# nrf9220_cellrf register map
Vendor: Nordic Semiconductor; Series: nRF92; File version: 1
CPU: CM0 r0p0, little endian, no MPU, no FPU, 2 interrupt priority bits, 33 interrupts
Registers are 32-bit, read-write, reset 0x0 unless marked. A register's access mark holds for its fields unless they carry their own. Offsets are from the block's base; [hi:lo] are bit positions.

## SX (part 2 of 3) — Ahma SX register map SX register map
Base 0x46147000
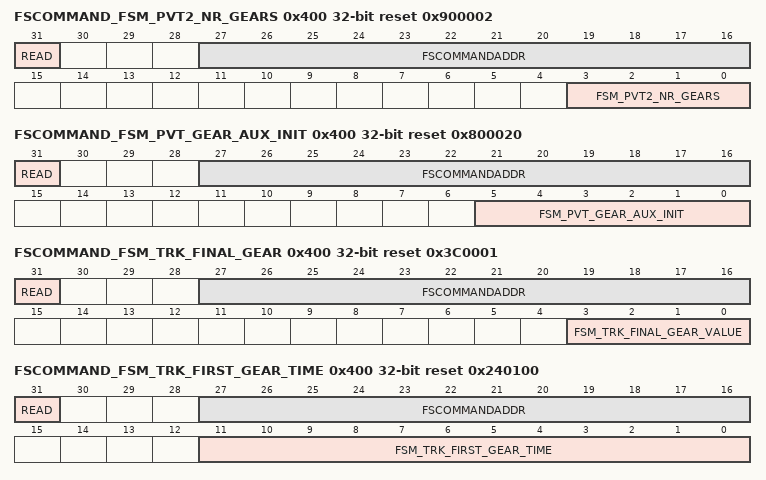
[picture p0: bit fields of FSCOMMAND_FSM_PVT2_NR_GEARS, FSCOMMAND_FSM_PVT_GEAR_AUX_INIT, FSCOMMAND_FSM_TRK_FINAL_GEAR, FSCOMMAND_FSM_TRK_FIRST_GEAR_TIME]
0x400 FSCOMMAND_FSM_PVT2_NR_GEARS reset 0x900002 (alternate view of FSCOMMAND_ANA_ISOLATION) — Send or receive command directly to/from the AdPllLte digital island. Only write to this register when FSASYNCBUSBUSY returns 0
  [31] READ — When 1, a read transaction is initiated. When the event COMPLETETRANS is set, read back this register
  [27:16] FSCOMMANDADDR — Address for the async interface. ALWAYS 0x90.
    144=FSM_PVT2_NR_GEARS_ADDR (ALWAYS 0x90.)
  [3:0] FSM_PVT2_NR_GEARS — The start value for the gear in NormPvt in PVT2 state. Used both in AdPllFsm and AdPllNormPvt. It affects how long we will be in the PVT2 state
0x400 FSCOMMAND_FSM_PVT_GEAR_AUX_INIT reset 0x800020 (alternate view of FSCOMMAND_ANA_ISOLATION) — Send or receive command directly to/from the AdPllLte digital island. Only write to this register when FSASYNCBUSBUSY returns 0
  [31] READ — When 1, a read transaction is initiated. When the event COMPLETETRANS is set, read back this register
  [27:16] FSCOMMANDADDR — Address for the async interface. ALWAYS 0x80.
    128=FSM_PVT_GEAR_AUX_INIT_ADDR (ALWAYS 0x80.)
  [5:0] FSM_PVT_GEAR_AUX_INIT — The start value for the gear_aux value in NormPvt. gear_aux is decremented at regular intervals, and is the upper bound for the current gear setting in NormPvt
0x400 FSCOMMAND_FSM_TRK_FINAL_GEAR reset 0x3C0001 (alternate view of FSCOMMAND_ANA_ISOLATION) — Send or receive command directly to/from the AdPllLte digital island. Only write to this register when FSASYNCBUSBUSY returns 0
  [31] READ — When 1, a read transaction is initiated. When the event COMPLETETRANS is set, read back this register
  [27:16] FSCOMMANDADDR — Address for the async interface. ALWAYS 0x3C.
    60=FSM_TRK_FINAL_GEAR_ADDR (ALWAYS 0x3C.)
  [3:0] FSM_TRK_FINAL_GEAR_VALUE — The gear setting used for the TRK bank after lock. Mainly a debug setting.
0x400 FSCOMMAND_FSM_TRK_FIRST_GEAR_TIME reset 0x240100 (alternate view of FSCOMMAND_ANA_ISOLATION) — Send or receive command directly to/from the AdPllLte digital island. Only write to this register when FSASYNCBUSBUSY returns 0
  [31] READ — When 1, a read transaction is initiated. When the event COMPLETETRANS is set, read back this register
  [27:16] FSCOMMANDADDR — Address for the async interface. ALWAYS 0x24.
    36=FSM_TRK_FIRST_GEAR_TIME_ADDR (ALWAYS 0x24.)
  [11:0] FSM_TRK_FIRST_GEAR_TIME — The number of cycles before we change gear in TRK state the first time. Used in AdPllFsm
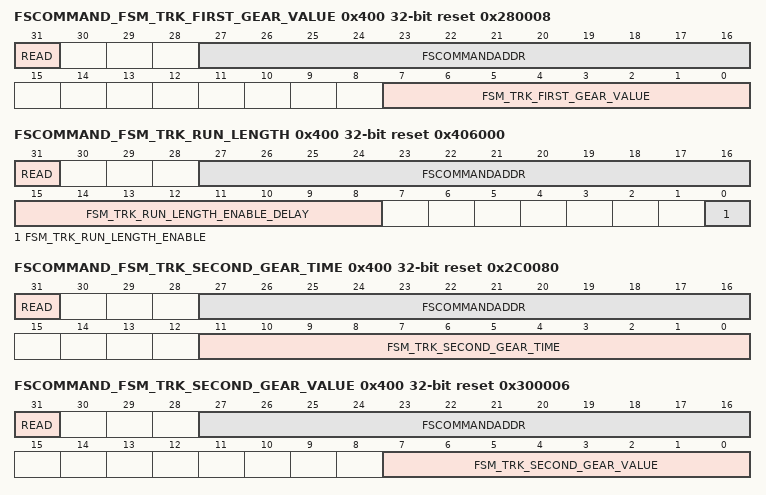
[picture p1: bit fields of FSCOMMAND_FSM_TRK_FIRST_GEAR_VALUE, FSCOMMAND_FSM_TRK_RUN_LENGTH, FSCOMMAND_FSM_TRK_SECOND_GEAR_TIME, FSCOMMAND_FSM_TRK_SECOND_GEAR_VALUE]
0x400 FSCOMMAND_FSM_TRK_FIRST_GEAR_VALUE reset 0x280008 (alternate view of FSCOMMAND_ANA_ISOLATION) — Send or receive command directly to/from the AdPllLte digital island. Only write to this register when FSASYNCBUSBUSY returns 0
  [31] READ — When 1, a read transaction is initiated. When the event COMPLETETRANS is set, read back this register
  [27:16] FSCOMMANDADDR — Address for the async interface. ALWAYS 0x28.
    40=FSM_TRK_FIRST_GEAR_VALUE_ADDR (ALWAYS 0x28.)
  [7:0] FSM_TRK_FIRST_GEAR_VALUE — The first gear value in TRK state
0x400 FSCOMMAND_FSM_TRK_RUN_LENGTH reset 0x406000 (alternate view of FSCOMMAND_ANA_ISOLATION) — Send or receive command directly to/from the AdPllLte digital island. Only write to this register when FSASYNCBUSBUSY returns 0
  [31] READ — When 1, a read transaction is initiated. When the event COMPLETETRANS is set, read back this register
  [27:16] FSCOMMANDADDR — Address for the async interface. ALWAYS 0x40.
    64=FSM_TRK_RUN_LENGTH_ADDR (ALWAYS 0x40.)
  [15:8] FSM_TRK_RUN_LENGTH_ENABLE_DELAY — Delay for enabling runlength delay
  [0] FSM_TRK_RUN_LENGTH_ENABLE — Selects whether to enable a feature where the gear in TRK state is slowed down if 'phe' stays the same for a while
0x400 FSCOMMAND_FSM_TRK_SECOND_GEAR_TIME reset 0x2C0080 (alternate view of FSCOMMAND_ANA_ISOLATION) — Send or receive command directly to/from the AdPllLte digital island. Only write to this register when FSASYNCBUSBUSY returns 0
  [31] READ — When 1, a read transaction is initiated. When the event COMPLETETRANS is set, read back this register
  [27:16] FSCOMMANDADDR — Address for the async interface. ALWAYS 0x2C.
    44=FSM_TRK_SECOND_GEAR_TIME_ADDR (ALWAYS 0x2C.)
  [11:0] FSM_TRK_SECOND_GEAR_TIME — The number of cycles before we change gear in TRK state the second time. Used in AdPllFsm
0x400 FSCOMMAND_FSM_TRK_SECOND_GEAR_VALUE reset 0x300006 (alternate view of FSCOMMAND_ANA_ISOLATION) — Send or receive command directly to/from the AdPllLte digital island. Only write to this register when FSASYNCBUSBUSY returns 0
  [31] READ — When 1, a read transaction is initiated. When the event COMPLETETRANS is set, read back this register
  [27:16] FSCOMMANDADDR — Address for the async interface. ALWAYS 0x30.
    48=FSM_TRK_SECOND_GEAR_VALUE_ADDR (ALWAYS 0x30.)
  [7:0] FSM_TRK_SECOND_GEAR_VALUE — The second gear value in TRK state
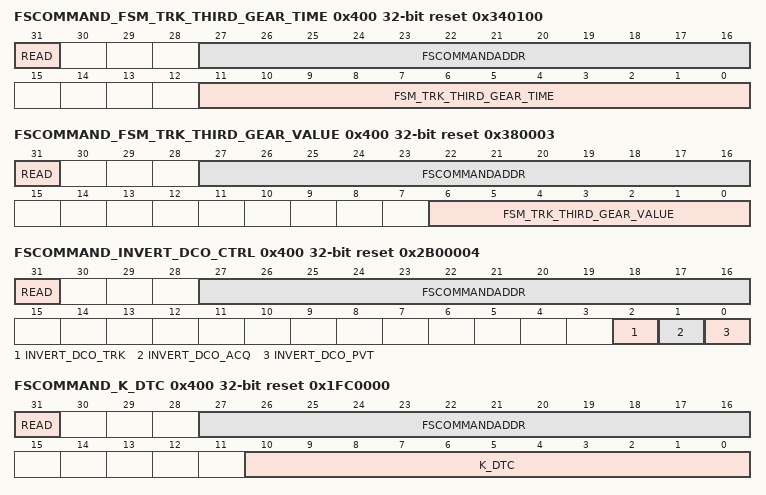
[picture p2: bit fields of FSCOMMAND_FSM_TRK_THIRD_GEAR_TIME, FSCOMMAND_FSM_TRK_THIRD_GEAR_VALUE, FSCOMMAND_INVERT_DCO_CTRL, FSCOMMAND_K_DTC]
0x400 FSCOMMAND_FSM_TRK_THIRD_GEAR_TIME reset 0x340100 (alternate view of FSCOMMAND_ANA_ISOLATION) — Send or receive command directly to/from the AdPllLte digital island. Only write to this register when FSASYNCBUSBUSY returns 0
  [31] READ — When 1, a read transaction is initiated. When the event COMPLETETRANS is set, read back this register
  [27:16] FSCOMMANDADDR — Address for the async interface. ALWAYS 0x34.
    52=FSM_TRK_THIRD_GEAR_TIME_ADDR (ALWAYS 0x34.)
  [11:0] FSM_TRK_THIRD_GEAR_TIME — The number of cycles before we change gear in TRK statethe third time. Used in AdPllFsm
0x400 FSCOMMAND_FSM_TRK_THIRD_GEAR_VALUE reset 0x380003 (alternate view of FSCOMMAND_ANA_ISOLATION) — Send or receive command directly to/from the AdPllLte digital island. Only write to this register when FSASYNCBUSBUSY returns 0
  [31] READ — When 1, a read transaction is initiated. When the event COMPLETETRANS is set, read back this register
  [27:16] FSCOMMANDADDR — Address for the async interface. ALWAYS 0x38.
    56=FSM_TRK_THIRD_GEAR_VALUE_ADDR (ALWAYS 0x38.)
  [6:0] FSM_TRK_THIRD_GEAR_VALUE — The third gear value in TRK state
0x400 FSCOMMAND_INVERT_DCO_CTRL reset 0x2B00004 (alternate view of FSCOMMAND_ANA_ISOLATION) — Send or receive command directly to/from the AdPllLte digital island. Only write to this register when FSASYNCBUSBUSY returns 0
  [31] READ — When 1, a read transaction is initiated. When the event COMPLETETRANS is set, read back this register
  [27:16] FSCOMMANDADDR — Address for the async interface. ALWAYS 0x2B0.
    0x2B0=INVERT_DCO_CTRL_ADDR (ALWAYS 0x2B0.)
  [2] INVERT_DCO_TRK — Invert DCO TRK control word
  [1] INVERT_DCO_ACQ — Invert DCO ACQ control word
  [0] INVERT_DCO_PVT — Invert DCO PVT control word
0x400 FSCOMMAND_K_DTC reset 0x1FC0000 (alternate view of FSCOMMAND_ANA_ISOLATION) — Send or receive command directly to/from the AdPllLte digital island. Only write to this register when FSASYNCBUSBUSY returns 0
  [31] READ — When 1, a read transaction is initiated. When the event COMPLETETRANS is set, read back this register
  [27:16] FSCOMMANDADDR — Address for the async interface. ALWAYS 0x1FC.
    0x1FC=K_DTC_ADDR (ALWAYS 0x1FC.)
  [10:0] K_DTC — Read the current kDTC estimate
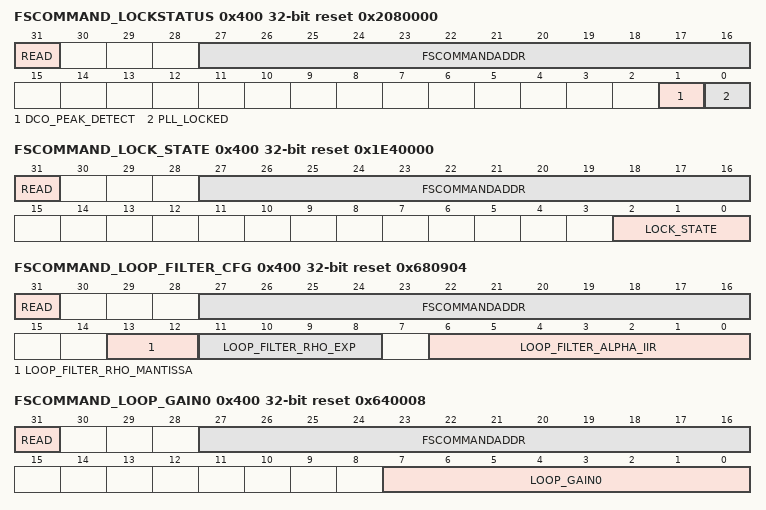
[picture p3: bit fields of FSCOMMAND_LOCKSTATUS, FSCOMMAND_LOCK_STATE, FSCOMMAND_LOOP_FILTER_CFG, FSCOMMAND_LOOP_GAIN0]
0x400 FSCOMMAND_LOCKSTATUS reset 0x2080000 (alternate view of FSCOMMAND_ANA_ISOLATION) — Send or receive command directly to/from the AdPllLte digital island. Only write to this register when FSASYNCBUSBUSY returns 0
  [31] READ — When 1, a read transaction is initiated. When the event COMPLETETRANS is set, read back this register
  [27:16] FSCOMMANDADDR — Address for the async interface. ALWAYS 0x208.
    0x208=LOCKSTATUS_ADDR (ALWAYS 0x208.)
  [1] DCO_PEAK_DETECT — Read the peakDetect signal from the analog domain
  [0] PLL_LOCKED — Read the pllLocked signal
0x400 FSCOMMAND_LOCK_STATE reset 0x1E40000 (alternate view of FSCOMMAND_ANA_ISOLATION) — Send or receive command directly to/from the AdPllLte digital island. Only write to this register when FSASYNCBUSBUSY returns 0
  [31] READ — When 1, a read transaction is initiated. When the event COMPLETETRANS is set, read back this register
  [27:16] FSCOMMANDADDR — Address for the async interface. ALWAYS 0x1E4.
    0x1E4=LOCK_STATE_ADDR (ALWAYS 0x1E4.)
  [2:0] LOCK_STATE — Read the current state in the locking state machine
0x400 FSCOMMAND_LOOP_FILTER_CFG reset 0x680904 (alternate view of FSCOMMAND_ANA_ISOLATION) — Send or receive command directly to/from the AdPllLte digital island. Only write to this register when FSASYNCBUSBUSY returns 0
  [31] READ — When 1, a read transaction is initiated. When the event COMPLETETRANS is set, read back this register
  [27:16] FSCOMMANDADDR — Address for the async interface. ALWAYS 0x68.
    104=LOOP_FILTER_CFG_ADDR (ALWAYS 0x68.)
  [13:12] LOOP_FILTER_RHO_MANTISSA — The rho value used in the loop filter in TRK bank control
  [11:8] LOOP_FILTER_RHO_EXP — The rho value used in the loop filter in TRK bank control
  [6:0] LOOP_FILTER_ALPHA_IIR — The alpha value used in the TRK bank control IIR filter (only when gear is 1. Otherwise, the alpha value is set to 64)
0x400 FSCOMMAND_LOOP_GAIN0 reset 0x640008 (alternate view of FSCOMMAND_ANA_ISOLATION) — Send or receive command directly to/from the AdPllLte digital island. Only write to this register when FSASYNCBUSBUSY returns 0
  [31] READ — When 1, a read transaction is initiated. When the event COMPLETETRANS is set, read back this register
  [27:16] FSCOMMANDADDR — Address for the async interface. ALWAYS 0x64.
    100=LOOP_GAIN0_ADDR (ALWAYS 0x64.)
  [7:0] LOOP_GAIN0 — How much the TDC output value is scaled and thus how much the error it will affect the loop. Default value.
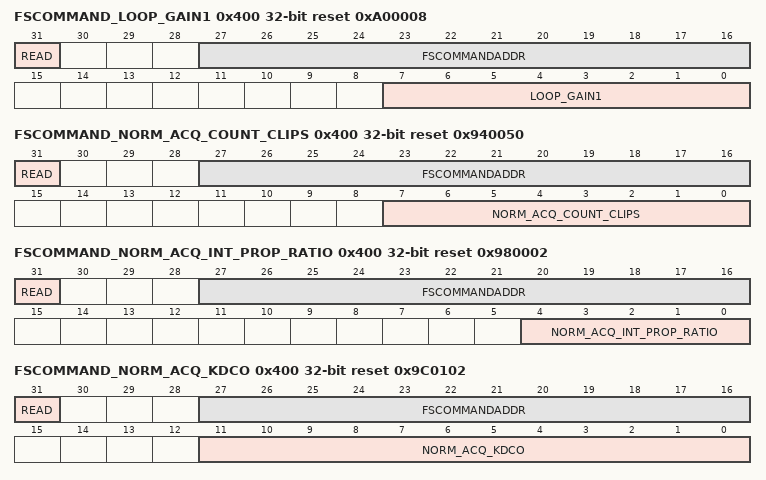
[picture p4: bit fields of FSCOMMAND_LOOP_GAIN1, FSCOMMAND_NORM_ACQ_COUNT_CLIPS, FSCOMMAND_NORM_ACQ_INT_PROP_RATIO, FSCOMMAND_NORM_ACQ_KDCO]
0x400 FSCOMMAND_LOOP_GAIN1 reset 0xA00008 (alternate view of FSCOMMAND_ANA_ISOLATION) — Send or receive command directly to/from the AdPllLte digital island. Only write to this register when FSASYNCBUSBUSY returns 0
  [31] READ — When 1, a read transaction is initiated. When the event COMPLETETRANS is set, read back this register
  [27:16] FSCOMMANDADDR — Address for the async interface. ALWAYS 0xA0.
    160=LOOP_GAIN1_ADDR (ALWAYS 0xA0.)
  [7:0] LOOP_GAIN1 — How much the TDC output value is scaled and thus how much the error it will affect the loop. Alternative value for fast frequency jump.
0x400 FSCOMMAND_NORM_ACQ_COUNT_CLIPS reset 0x940050 (alternate view of FSCOMMAND_ANA_ISOLATION) — Send or receive command directly to/from the AdPllLte digital island. Only write to this register when FSASYNCBUSBUSY returns 0
  [31] READ — When 1, a read transaction is initiated. When the event COMPLETETRANS is set, read back this register
  [27:16] FSCOMMANDADDR — Address for the async interface. ALWAYS 0x94.
    148=NORM_ACQ_COUNT_CLIPS_ADDR (ALWAYS 0x94.)
  [7:0] NORM_ACQ_COUNT_CLIPS — The ACQ bank overflow happens if the value stays outside min/max of ACQ for more than this number of cycles. In the case of overflow the PVT capacitor bank control value is incremented
0x400 FSCOMMAND_NORM_ACQ_INT_PROP_RATIO reset 0x980002 (alternate view of FSCOMMAND_ANA_ISOLATION) — Send or receive command directly to/from the AdPllLte digital island. Only write to this register when FSASYNCBUSBUSY returns 0
  [31] READ — When 1, a read transaction is initiated. When the event COMPLETETRANS is set, read back this register
  [27:16] FSCOMMANDADDR — Address for the async interface. ALWAYS 0x98.
    152=NORM_ACQ_INT_PROP_RATIO_ADDR (ALWAYS 0x98.)
  [4:0] NORM_ACQ_INT_PROP_RATIO — The integral path in the ACQ capacitor control will be right-shifted (divided by 2 N times) this number. It basically selects how big impact the integral path has vs the proportional path. (Bigger number - less impact)
0x400 FSCOMMAND_NORM_ACQ_KDCO reset 0x9C0102 (alternate view of FSCOMMAND_ANA_ISOLATION) — Send or receive command directly to/from the AdPllLte digital island. Only write to this register when FSASYNCBUSBUSY returns 0
  [31] READ — When 1, a read transaction is initiated. When the event COMPLETETRANS is set, read back this register
  [27:16] FSCOMMANDADDR — Address for the async interface. ALWAYS 0x9C.
    156=NORM_ACQ_KDCO_ADDR (ALWAYS 0x9C.)
  [11:0] NORM_ACQ_KDCO — The estimated kDCO for steps of the control word in the ACQ capacitor bank. Used in AdPllNormPvt to scale the error input.
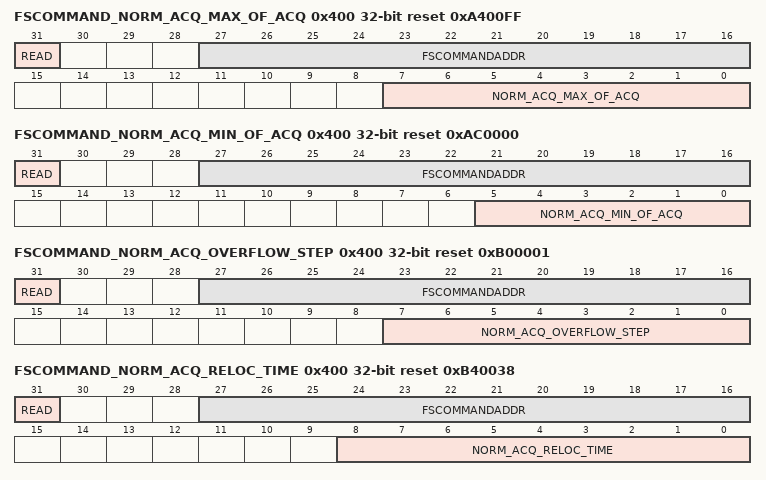
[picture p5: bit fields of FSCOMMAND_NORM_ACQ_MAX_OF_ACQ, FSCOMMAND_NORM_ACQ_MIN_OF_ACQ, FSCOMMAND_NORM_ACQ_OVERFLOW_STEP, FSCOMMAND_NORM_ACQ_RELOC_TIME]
0x400 FSCOMMAND_NORM_ACQ_MAX_OF_ACQ reset 0xA400FF (alternate view of FSCOMMAND_ANA_ISOLATION) — Send or receive command directly to/from the AdPllLte digital island. Only write to this register when FSASYNCBUSBUSY returns 0
  [31] READ — When 1, a read transaction is initiated. When the event COMPLETETRANS is set, read back this register
  [27:16] FSCOMMANDADDR — Address for the async interface. ALWAYS 0xA4.
    164=NORM_ACQ_MAX_OF_ACQ_ADDR (ALWAYS 0xA4.)
  [7:0] NORM_ACQ_MAX_OF_ACQ — The allowed maximum value for the control word for the ACQ capacitor bank before the control word for the PVT capacitor bank will be incremented
0x400 FSCOMMAND_NORM_ACQ_MIN_OF_ACQ reset 0xAC0000 (alternate view of FSCOMMAND_ANA_ISOLATION) — Send or receive command directly to/from the AdPllLte digital island. Only write to this register when FSASYNCBUSBUSY returns 0
  [31] READ — When 1, a read transaction is initiated. When the event COMPLETETRANS is set, read back this register
  [27:16] FSCOMMANDADDR — Address for the async interface. ALWAYS 0xAC.
    172=NORM_ACQ_MIN_OF_ACQ_ADDR (ALWAYS 0xAC.)
  [5:0] NORM_ACQ_MIN_OF_ACQ — The allowed maximum value for the control word for the ACQ capacitor bank before the control word for the PVT capacitor bank will be incremented
0x400 FSCOMMAND_NORM_ACQ_OVERFLOW_STEP reset 0xB00001 (alternate view of FSCOMMAND_ANA_ISOLATION) — Send or receive command directly to/from the AdPllLte digital island. Only write to this register when FSASYNCBUSBUSY returns 0
  [31] READ — When 1, a read transaction is initiated. When the event COMPLETETRANS is set, read back this register
  [27:16] FSCOMMANDADDR — Address for the async interface. ALWAYS 0xB0.
    176=NORM_ACQ_OVERFLOW_STEP_ADDR (ALWAYS 0xB0.)
  [7:0] NORM_ACQ_OVERFLOW_STEP — The number of steps to adjust the ACQ capacitor bank when an overflow is detected in the TRK capacitor bank
0x400 FSCOMMAND_NORM_ACQ_RELOC_TIME reset 0xB40038 (alternate view of FSCOMMAND_ANA_ISOLATION) — Send or receive command directly to/from the AdPllLte digital island. Only write to this register when FSASYNCBUSBUSY returns 0
  [31] READ — When 1, a read transaction is initiated. When the event COMPLETETRANS is set, read back this register
  [27:16] FSCOMMANDADDR — Address for the async interface. ALWAYS 0xB4.
    180=NORM_ACQ_RELOC_TIME_ADDR (ALWAYS 0xB4.)
  [8:0] NORM_ACQ_RELOC_TIME — Minimum time between ACQ overflows
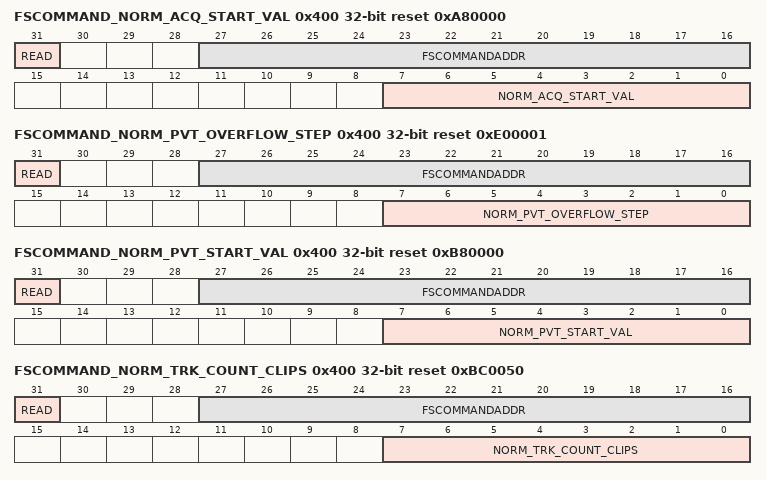
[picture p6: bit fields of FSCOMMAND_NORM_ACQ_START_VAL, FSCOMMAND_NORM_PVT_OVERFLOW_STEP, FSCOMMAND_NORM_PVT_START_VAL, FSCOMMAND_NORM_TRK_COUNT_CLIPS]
0x400 FSCOMMAND_NORM_ACQ_START_VAL reset 0xA80000 (alternate view of FSCOMMAND_ANA_ISOLATION) — Send or receive command directly to/from the AdPllLte digital island. Only write to this register when FSASYNCBUSBUSY returns 0
  [31] READ — When 1, a read transaction is initiated. When the event COMPLETETRANS is set, read back this register
  [27:16] FSCOMMANDADDR — Address for the async interface. ALWAYS 0xA8.
    168=NORM_ACQ_START_VAL_ADDR (ALWAYS 0xA8.)
  [7:0] NORM_ACQ_START_VAL — The start value for the control word for the ACQ capactior bank (signed offset from mid code)
0x400 FSCOMMAND_NORM_PVT_OVERFLOW_STEP reset 0xE00001 (alternate view of FSCOMMAND_ANA_ISOLATION) — Send or receive command directly to/from the AdPllLte digital island. Only write to this register when FSASYNCBUSBUSY returns 0
  [31] READ — When 1, a read transaction is initiated. When the event COMPLETETRANS is set, read back this register
  [27:16] FSCOMMANDADDR — Address for the async interface. ALWAYS 0xE0.
    224=NORM_PVT_OVERFLOW_STEP_ADDR (ALWAYS 0xE0.)
  [7:0] NORM_PVT_OVERFLOW_STEP — Number of correction steps to make in NormPvt when there is an overflow being indicated by NormAcq
0x400 FSCOMMAND_NORM_PVT_START_VAL reset 0xB80000 (alternate view of FSCOMMAND_ANA_ISOLATION) — Send or receive command directly to/from the AdPllLte digital island. Only write to this register when FSASYNCBUSBUSY returns 0
  [31] READ — When 1, a read transaction is initiated. When the event COMPLETETRANS is set, read back this register
  [27:16] FSCOMMANDADDR — Address for the async interface. ALWAYS 0xB8.
    184=NORM_PVT_START_VAL_ADDR (ALWAYS 0xB8.)
  [7:0] NORM_PVT_START_VAL — The start value for the control word for the PVT capacitor bank (signed offset from mid code)
0x400 FSCOMMAND_NORM_TRK_COUNT_CLIPS reset 0xBC0050 (alternate view of FSCOMMAND_ANA_ISOLATION) — Send or receive command directly to/from the AdPllLte digital island. Only write to this register when FSASYNCBUSBUSY returns 0
  [31] READ — When 1, a read transaction is initiated. When the event COMPLETETRANS is set, read back this register
  [27:16] FSCOMMANDADDR — Address for the async interface. ALWAYS 0xBC.
    188=NORM_TRK_COUNT_CLIPS_ADDR (ALWAYS 0xBC.)
  [7:0] NORM_TRK_COUNT_CLIPS — The TRK bank overflow happens if the value stays outside min/max of TRK for more than this number of cycles. If it does, we signal an TRK bank overflow and bump the ACQ control word, and lower the TRK control word.
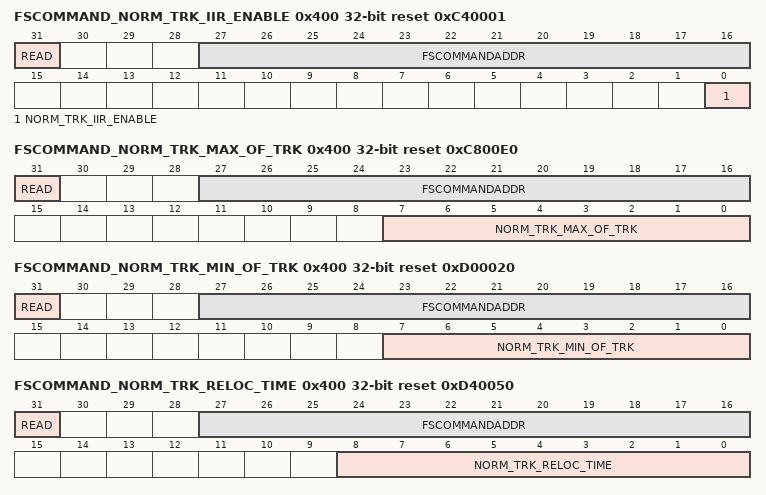
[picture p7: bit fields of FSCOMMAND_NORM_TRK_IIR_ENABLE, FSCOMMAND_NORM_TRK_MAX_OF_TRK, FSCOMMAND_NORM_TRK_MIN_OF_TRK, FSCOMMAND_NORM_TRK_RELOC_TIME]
0x400 FSCOMMAND_NORM_TRK_IIR_ENABLE reset 0xC40001 (alternate view of FSCOMMAND_ANA_ISOLATION) — Send or receive command directly to/from the AdPllLte digital island. Only write to this register when FSASYNCBUSBUSY returns 0
  [31] READ — When 1, a read transaction is initiated. When the event COMPLETETRANS is set, read back this register
  [27:16] FSCOMMANDADDR — Address for the async interface. ALWAYS 0xC4.
    196=NORM_TRK_IIR_ENABLE_ADDR (ALWAYS 0xC4.)
  [0] NORM_TRK_IIR_ENABLE — Enable the IIR filter in the TRK bank control
0x400 FSCOMMAND_NORM_TRK_MAX_OF_TRK reset 0xC800E0 (alternate view of FSCOMMAND_ANA_ISOLATION) — Send or receive command directly to/from the AdPllLte digital island. Only write to this register when FSASYNCBUSBUSY returns 0
  [31] READ — When 1, a read transaction is initiated. When the event COMPLETETRANS is set, read back this register
  [27:16] FSCOMMANDADDR — Address for the async interface. ALWAYS 0xC8.
    200=NORM_TRK_MAX_OF_TRK_ADDR (ALWAYS 0xC8.)
  [7:0] NORM_TRK_MAX_OF_TRK — Max allowed value in the TRK control before the safety mechanism starts counting
0x400 FSCOMMAND_NORM_TRK_MIN_OF_TRK reset 0xD00020 (alternate view of FSCOMMAND_ANA_ISOLATION) — Send or receive command directly to/from the AdPllLte digital island. Only write to this register when FSASYNCBUSBUSY returns 0
  [31] READ — When 1, a read transaction is initiated. When the event COMPLETETRANS is set, read back this register
  [27:16] FSCOMMANDADDR — Address for the async interface. ALWAYS 0xD0.
    208=NORM_TRK_MIN_OF_TRK_ADDR (ALWAYS 0xD0.)
  [7:0] NORM_TRK_MIN_OF_TRK — Min allowed value in the TRK control before the safety mechanism starts counting
0x400 FSCOMMAND_NORM_TRK_RELOC_TIME reset 0xD40050 (alternate view of FSCOMMAND_ANA_ISOLATION) — Send or receive command directly to/from the AdPllLte digital island. Only write to this register when FSASYNCBUSBUSY returns 0
  [31] READ — When 1, a read transaction is initiated. When the event COMPLETETRANS is set, read back this register
  [27:16] FSCOMMANDADDR — Address for the async interface. ALWAYS 0xD4.
    212=NORM_TRK_RELOC_TIME_ADDR (ALWAYS 0xD4.)
  [8:0] NORM_TRK_RELOC_TIME — Minimum time before and between TRK overflows
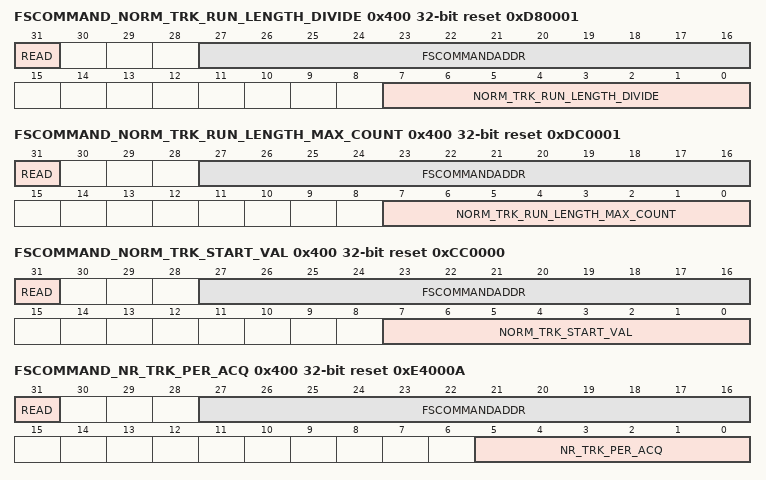
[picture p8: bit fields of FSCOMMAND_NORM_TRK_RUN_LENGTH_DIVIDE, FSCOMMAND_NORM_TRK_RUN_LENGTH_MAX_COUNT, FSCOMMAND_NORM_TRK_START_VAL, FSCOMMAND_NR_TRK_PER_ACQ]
0x400 FSCOMMAND_NORM_TRK_RUN_LENGTH_DIVIDE reset 0xD80001 (alternate view of FSCOMMAND_ANA_ISOLATION) — Send or receive command directly to/from the AdPllLte digital island. Only write to this register when FSASYNCBUSBUSY returns 0
  [31] READ — When 1, a read transaction is initiated. When the event COMPLETETRANS is set, read back this register
  [27:16] FSCOMMANDADDR — Address for the async interface. ALWAYS 0xD8.
    216=NORM_TRK_RUN_LENGTH_DIVIDE_ADDR (ALWAYS 0xD8.)
  [7:0] NORM_TRK_RUN_LENGTH_DIVIDE — When using run length division. This number decides how much to divide
0x400 FSCOMMAND_NORM_TRK_RUN_LENGTH_MAX_COUNT reset 0xDC0001 (alternate view of FSCOMMAND_ANA_ISOLATION) — Send or receive command directly to/from the AdPllLte digital island. Only write to this register when FSASYNCBUSBUSY returns 0
  [31] READ — When 1, a read transaction is initiated. When the event COMPLETETRANS is set, read back this register
  [27:16] FSCOMMANDADDR — Address for the async interface. ALWAYS 0xDC.
    220=NORM_TRK_RUN_LENGTH_MAX_COUNT_ADDR (ALWAYS 0xDC.)
  [7:0] NORM_TRK_RUN_LENGTH_MAX_COUNT — The max value to count to when using run length division
0x400 FSCOMMAND_NORM_TRK_START_VAL reset 0xCC0000 (alternate view of FSCOMMAND_ANA_ISOLATION) — Send or receive command directly to/from the AdPllLte digital island. Only write to this register when FSASYNCBUSBUSY returns 0
  [31] READ — When 1, a read transaction is initiated. When the event COMPLETETRANS is set, read back this register
  [27:16] FSCOMMANDADDR — Address for the async interface. ALWAYS 0xCC.
    204=NORM_TRK_START_VAL_ADDR (ALWAYS 0xCC.)
  [7:0] NORM_TRK_START_VAL — Start value for the TRK bank control (signed offset from mid code)
0x400 FSCOMMAND_NR_TRK_PER_ACQ reset 0xE4000A (alternate view of FSCOMMAND_ANA_ISOLATION) — Send or receive command directly to/from the AdPllLte digital island. Only write to this register when FSASYNCBUSBUSY returns 0
  [31] READ — When 1, a read transaction is initiated. When the event COMPLETETRANS is set, read back this register
  [27:16] FSCOMMANDADDR — Address for the async interface. ALWAYS 0xE4.
    228=NR_TRK_PER_ACQ_ADDR (ALWAYS 0xE4.)
  [5:0] NR_TRK_PER_ACQ — The ACQ capacitance divided by TRK capacitance. This is used to know how much to subtract from the TRK control value when the ACQ control value is bumped.
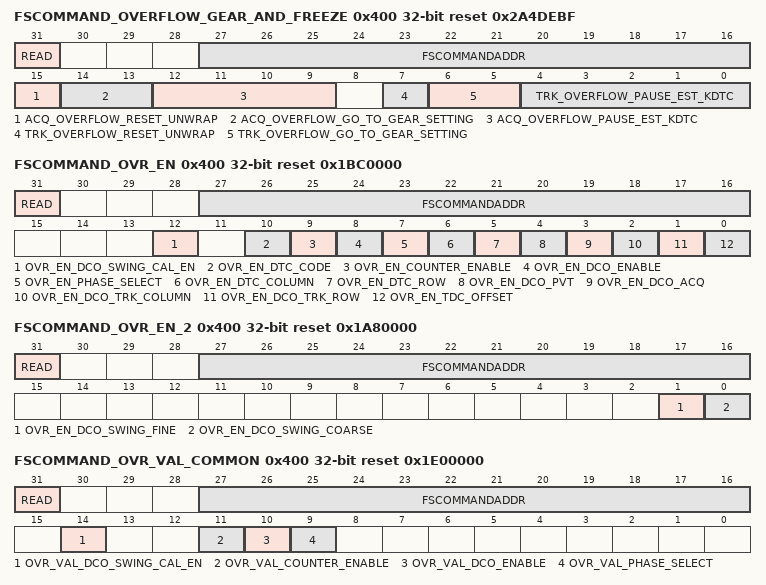
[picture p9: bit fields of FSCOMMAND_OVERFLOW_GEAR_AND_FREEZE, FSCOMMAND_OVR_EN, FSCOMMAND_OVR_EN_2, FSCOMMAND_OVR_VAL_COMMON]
0x400 FSCOMMAND_OVERFLOW_GEAR_AND_FREEZE reset 0x2A4DEBF (alternate view of FSCOMMAND_ANA_ISOLATION) — Send or receive command directly to/from the AdPllLte digital island. Only write to this register when FSASYNCBUSBUSY returns 0
  [31] READ — When 1, a read transaction is initiated. When the event COMPLETETRANS is set, read back this register
  [27:16] FSCOMMANDADDR — Address for the async interface. ALWAYS 0x2A4.
    0x2A4=OVERFLOW_GEAR_AND_FREEZE_ADDR (ALWAYS 0x2A4.)
  [15] ACQ_OVERFLOW_RESET_UNWRAP — Reset the unwrap accumulator when overflowing the ACQ bank and stepping the PVT bank
  [14:13] ACQ_OVERFLOW_GO_TO_GEAR_SETTING — Go to one of the configured gear settings when the ACQ bank overflows. 0: off, 1: Go to FSM_TRK_THIRD_GEAR, 2: Go to FSM_TRK_SECOND_GEAR, 3: Go to FSM_TRK_FIRST_GEAR
  [12:9] ACQ_OVERFLOW_PAUSE_EST_KDTC — When the ACQ bank overflows, we disable the input to the kDTC estimator for a while (multiplied by 16)
  [7] TRK_OVERFLOW_RESET_UNWRAP — Reset the unwrap accumulator when overflowing the TRK bank and stepping the ACQ bank
  [6:5] TRK_OVERFLOW_GO_TO_GEAR_SETTING — Go to one of the configured gear settings when the TRK bank overflows. 0: off, 1: Go to FSM_TRK_THIRD_GEAR, 2: Go to FSM_TRK_SECOND_GEAR, 3: Go to FSM_TRK_FIRST_GEAR
  [4:0] TRK_OVERFLOW_PAUSE_EST_KDTC — When the TRK bank overflows, we disable the input to the kDTC estimator for a while (multiplied by 8)
0x400 FSCOMMAND_OVR_EN reset 0x1BC0000 (alternate view of FSCOMMAND_ANA_ISOLATION) — Send or receive command directly to/from the AdPllLte digital island. Only write to this register when FSASYNCBUSBUSY returns 0
  [31] READ — When 1, a read transaction is initiated. When the event COMPLETETRANS is set, read back this register
  [27:16] FSCOMMANDADDR — Address for the async interface. ALWAYS 0x1BC.
    0x1BC=OVR_EN_ADDR (ALWAYS 0x1BC.)
  [12] OVR_EN_DCO_SWING_CAL_EN — Override enable for dcoSwingCalEn
  [10] OVR_EN_DTC_CODE — Override enable for the DTC control code
  [9] OVR_EN_COUNTER_ENABLE — Override enable for fsCounterEnable
  [8] OVR_EN_DCO_ENABLE — Override enable for dcoEnable
  [7] OVR_EN_PHASE_SELECT — Override enable for phaseSelect
  [6] OVR_EN_DTC_COLUMN — Override enable for dtcColumn
  [5] OVR_EN_DTC_ROW — Override enable for dtcRow
  [4] OVR_EN_DCO_PVT — Override enable for dcoPvt
  [3] OVR_EN_DCO_ACQ — Override enable for dcoAcq
  [2] OVR_EN_DCO_TRK_COLUMN — Override enable for dcoTrkColumn
  [1] OVR_EN_DCO_TRK_ROW — Override enable for dcoTrkRow
  [0] OVR_EN_TDC_OFFSET — Override enable for TDC offset value0
0x400 FSCOMMAND_OVR_EN_2 reset 0x1A80000 (alternate view of FSCOMMAND_ANA_ISOLATION) — Send or receive command directly to/from the AdPllLte digital island. Only write to this register when FSASYNCBUSBUSY returns 0
  [31] READ — When 1, a read transaction is initiated. When the event COMPLETETRANS is set, read back this register
  [27:16] FSCOMMANDADDR — Address for the async interface. ALWAYS 0x1A8.
    0x1A8=OVR_EN_2_ADDR (ALWAYS 0x1A8.)
  [1] OVR_EN_DCO_SWING_FINE — Override enable for fine DCO swing
  [0] OVR_EN_DCO_SWING_COARSE — Override enable for coarse DCO swing
0x400 FSCOMMAND_OVR_VAL_COMMON reset 0x1E00000 (alternate view of FSCOMMAND_ANA_ISOLATION) — Send or receive command directly to/from the AdPllLte digital island. Only write to this register when FSASYNCBUSBUSY returns 0
  [31] READ — When 1, a read transaction is initiated. When the event COMPLETETRANS is set, read back this register
  [27:16] FSCOMMANDADDR — Address for the async interface. ALWAYS 0x1E0.
    0x1E0=OVR_VAL_COMMON_ADDR (ALWAYS 0x1E0.)
  [14] OVR_VAL_DCO_SWING_CAL_EN — Override value for dcoSwingCalEn
  [11] OVR_VAL_COUNTER_ENABLE — Override value for fsCounterEnable
  [10] OVR_VAL_DCO_ENABLE — Override value for dcoEnable
  [9] OVR_VAL_PHASE_SELECT — Override value for phaseSelect
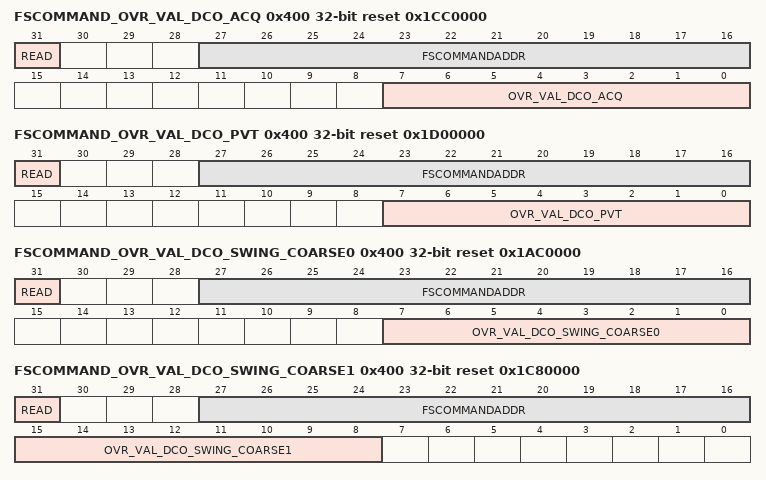
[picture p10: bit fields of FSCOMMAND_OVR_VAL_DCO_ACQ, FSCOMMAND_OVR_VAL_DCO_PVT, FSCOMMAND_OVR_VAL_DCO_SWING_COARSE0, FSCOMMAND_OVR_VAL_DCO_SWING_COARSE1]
0x400 FSCOMMAND_OVR_VAL_DCO_ACQ reset 0x1CC0000 (alternate view of FSCOMMAND_ANA_ISOLATION) — Send or receive command directly to/from the AdPllLte digital island. Only write to this register when FSASYNCBUSBUSY returns 0
  [31] READ — When 1, a read transaction is initiated. When the event COMPLETETRANS is set, read back this register
  [27:16] FSCOMMANDADDR — Address for the async interface. ALWAYS 0x1CC.
    0x1CC=OVR_VAL_DCO_ACQ_ADDR (ALWAYS 0x1CC.)
  [7:0] OVR_VAL_DCO_ACQ — Override value for dcoAcq
0x400 FSCOMMAND_OVR_VAL_DCO_PVT reset 0x1D00000 (alternate view of FSCOMMAND_ANA_ISOLATION) — Send or receive command directly to/from the AdPllLte digital island. Only write to this register when FSASYNCBUSBUSY returns 0
  [31] READ — When 1, a read transaction is initiated. When the event COMPLETETRANS is set, read back this register
  [27:16] FSCOMMANDADDR — Address for the async interface. ALWAYS 0x1D0.
    0x1D0=OVR_VAL_DCO_PVT_ADDR (ALWAYS 0x1D0.)
  [7:0] OVR_VAL_DCO_PVT — Override value for dcoPvt
0x400 FSCOMMAND_OVR_VAL_DCO_SWING_COARSE0 reset 0x1AC0000 (alternate view of FSCOMMAND_ANA_ISOLATION) — Send or receive command directly to/from the AdPllLte digital island. Only write to this register when FSASYNCBUSBUSY returns 0
  [31] READ — When 1, a read transaction is initiated. When the event COMPLETETRANS is set, read back this register
  [27:16] FSCOMMANDADDR — Address for the async interface. ALWAYS 0x1AC.
    0x1AC=OVR_VAL_DCO_SWING_COARSE0_ADDR (ALWAYS 0x1AC.)
  [7:0] OVR_VAL_DCO_SWING_COARSE0 — Override value0 for the coarse DCO swing. Also used in fast frequency jumps
0x400 FSCOMMAND_OVR_VAL_DCO_SWING_COARSE1 reset 0x1C80000 (alternate view of FSCOMMAND_ANA_ISOLATION) — Send or receive command directly to/from the AdPllLte digital island. Only write to this register when FSASYNCBUSBUSY returns 0
  [31] READ — When 1, a read transaction is initiated. When the event COMPLETETRANS is set, read back this register
  [27:16] FSCOMMANDADDR — Address for the async interface. ALWAYS 0x1C8.
    0x1C8=OVR_VAL_DCO_SWING_COARSE1_ADDR (ALWAYS 0x1C8.)
  [15:8] OVR_VAL_DCO_SWING_COARSE1 — Override value1 for the coarse DCO swing. Only used in fast frequency jumps
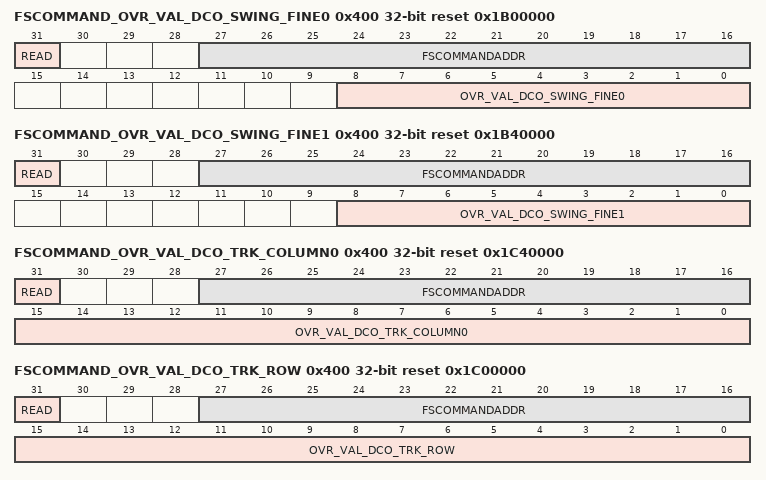
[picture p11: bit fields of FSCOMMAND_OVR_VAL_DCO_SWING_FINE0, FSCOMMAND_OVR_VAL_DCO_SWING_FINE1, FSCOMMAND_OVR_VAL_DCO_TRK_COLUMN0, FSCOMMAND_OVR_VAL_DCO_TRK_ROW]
0x400 FSCOMMAND_OVR_VAL_DCO_SWING_FINE0 reset 0x1B00000 (alternate view of FSCOMMAND_ANA_ISOLATION) — Send or receive command directly to/from the AdPllLte digital island. Only write to this register when FSASYNCBUSBUSY returns 0
  [31] READ — When 1, a read transaction is initiated. When the event COMPLETETRANS is set, read back this register
  [27:16] FSCOMMANDADDR — Address for the async interface. ALWAYS 0x1B0.
    0x1B0=OVR_VAL_DCO_SWING_FINE0_ADDR (ALWAYS 0x1B0.)
  [8:0] OVR_VAL_DCO_SWING_FINE0 — Override value0 for the fine DCO swing. Also used in fast frequency jumps
0x400 FSCOMMAND_OVR_VAL_DCO_SWING_FINE1 reset 0x1B40000 (alternate view of FSCOMMAND_ANA_ISOLATION) — Send or receive command directly to/from the AdPllLte digital island. Only write to this register when FSASYNCBUSBUSY returns 0
  [31] READ — When 1, a read transaction is initiated. When the event COMPLETETRANS is set, read back this register
  [27:16] FSCOMMANDADDR — Address for the async interface. ALWAYS 0x1B4.
    0x1B4=OVR_VAL_DCO_SWING_FINE1_ADDR (ALWAYS 0x1B4.)
  [8:0] OVR_VAL_DCO_SWING_FINE1 — Override value1 for the fine DCO swing. Only used in fast frequency jumps
0x400 FSCOMMAND_OVR_VAL_DCO_TRK_COLUMN0 reset 0x1C40000 (alternate view of FSCOMMAND_ANA_ISOLATION) — Send or receive command directly to/from the AdPllLte digital island. Only write to this register when FSASYNCBUSBUSY returns 0
  [31] READ — When 1, a read transaction is initiated. When the event COMPLETETRANS is set, read back this register
  [27:16] FSCOMMANDADDR — Address for the async interface. ALWAYS 0x1C4.
    0x1C4=OVR_VAL_DCO_TRK_COLUMN0_ADDR (ALWAYS 0x1C4.)
  [15:0] OVR_VAL_DCO_TRK_COLUMN0 — Override value for dcoTrkColumn0
0x400 FSCOMMAND_OVR_VAL_DCO_TRK_ROW reset 0x1C00000 (alternate view of FSCOMMAND_ANA_ISOLATION) — Send or receive command directly to/from the AdPllLte digital island. Only write to this register when FSASYNCBUSBUSY returns 0
  [31] READ — When 1, a read transaction is initiated. When the event COMPLETETRANS is set, read back this register
  [27:16] FSCOMMANDADDR — Address for the async interface. ALWAYS 0x1C0.
    0x1C0=OVR_VAL_DCO_TRK_ROW_ADDR (ALWAYS 0x1C0.)
  [15:0] OVR_VAL_DCO_TRK_ROW — Override value for dcoTrkRow
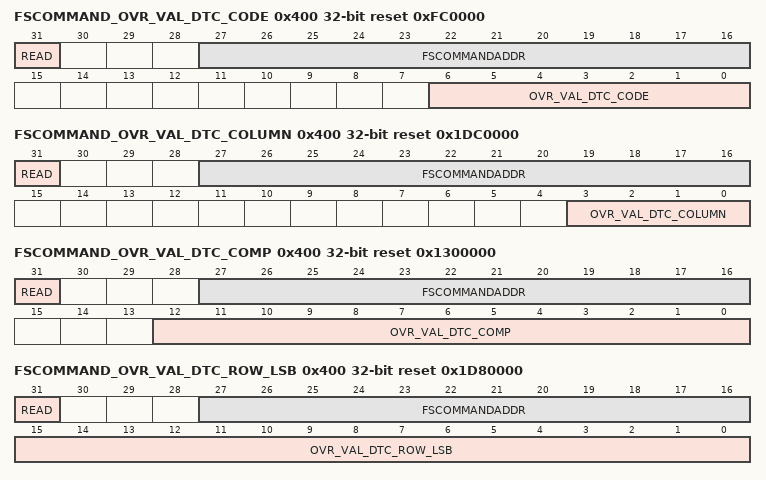
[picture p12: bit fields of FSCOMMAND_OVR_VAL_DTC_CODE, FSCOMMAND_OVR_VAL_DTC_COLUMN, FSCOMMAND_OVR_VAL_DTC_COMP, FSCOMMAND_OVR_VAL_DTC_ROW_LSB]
0x400 FSCOMMAND_OVR_VAL_DTC_CODE reset 0xFC0000 (alternate view of FSCOMMAND_ANA_ISOLATION) — Send or receive command directly to/from the AdPllLte digital island. Only write to this register when FSASYNCBUSBUSY returns 0
  [31] READ — When 1, a read transaction is initiated. When the event COMPLETETRANS is set, read back this register
  [27:16] FSCOMMANDADDR — Address for the async interface. ALWAYS 0xFC.
    252=OVR_VAL_DTC_CODE_ADDR (ALWAYS 0xFC.)
  [6:0] OVR_VAL_DTC_CODE — Override value for the DTC control code (is overridden after the kdtc scaling)
0x400 FSCOMMAND_OVR_VAL_DTC_COLUMN reset 0x1DC0000 (alternate view of FSCOMMAND_ANA_ISOLATION) — Send or receive command directly to/from the AdPllLte digital island. Only write to this register when FSASYNCBUSBUSY returns 0
  [31] READ — When 1, a read transaction is initiated. When the event COMPLETETRANS is set, read back this register
  [27:16] FSCOMMANDADDR — Address for the async interface. ALWAYS 0x1DC.
    0x1DC=OVR_VAL_DTC_COLUMN_ADDR (ALWAYS 0x1DC.)
  [3:0] OVR_VAL_DTC_COLUMN — Override value for dtcColumn
0x400 FSCOMMAND_OVR_VAL_DTC_COMP reset 0x1300000 (alternate view of FSCOMMAND_ANA_ISOLATION) — Send or receive command directly to/from the AdPllLte digital island. Only write to this register when FSASYNCBUSBUSY returns 0
  [31] READ — When 1, a read transaction is initiated. When the event COMPLETETRANS is set, read back this register
  [27:16] FSCOMMANDADDR — Address for the async interface. ALWAYS 0x130.
    0x130=OVR_VAL_DTC_COMP_ADDR (ALWAYS 0x130.)
  [12:0] OVR_VAL_DTC_COMP — Overridden compensation value for duty cycle in DtcCtrl. Used both when DtcComp is disabled and when ovrValDtcComp is not 0
0x400 FSCOMMAND_OVR_VAL_DTC_ROW_LSB reset 0x1D80000 (alternate view of FSCOMMAND_ANA_ISOLATION) — Send or receive command directly to/from the AdPllLte digital island. Only write to this register when FSASYNCBUSBUSY returns 0
  [31] READ — When 1, a read transaction is initiated. When the event COMPLETETRANS is set, read back this register
  [27:16] FSCOMMANDADDR — Address for the async interface. ALWAYS 0x1D8.
    0x1D8=OVR_VAL_DTC_ROW_LSB_ADDR (ALWAYS 0x1D8.)
  [15:0] OVR_VAL_DTC_ROW_LSB — Override value LSB bits for dtcRow
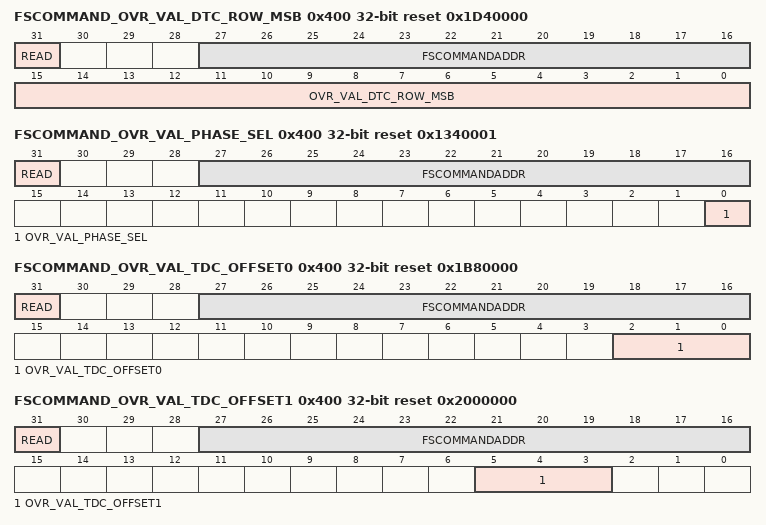
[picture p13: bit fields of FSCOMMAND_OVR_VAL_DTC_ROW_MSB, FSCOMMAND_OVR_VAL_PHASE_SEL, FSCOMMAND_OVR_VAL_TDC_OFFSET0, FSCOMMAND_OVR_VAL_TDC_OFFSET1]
0x400 FSCOMMAND_OVR_VAL_DTC_ROW_MSB reset 0x1D40000 (alternate view of FSCOMMAND_ANA_ISOLATION) — Send or receive command directly to/from the AdPllLte digital island. Only write to this register when FSASYNCBUSBUSY returns 0
  [31] READ — When 1, a read transaction is initiated. When the event COMPLETETRANS is set, read back this register
  [27:16] FSCOMMANDADDR — Address for the async interface. ALWAYS 0x1D4.
    0x1D4=OVR_VAL_DTC_ROW_MSB_ADDR (ALWAYS 0x1D4.)
  [15:0] OVR_VAL_DTC_ROW_MSB — Override value MSB bits for dtcRow
0x400 FSCOMMAND_OVR_VAL_PHASE_SEL reset 0x1340001 (alternate view of FSCOMMAND_ANA_ISOLATION) — Send or receive command directly to/from the AdPllLte digital island. Only write to this register when FSASYNCBUSBUSY returns 0
  [31] READ — When 1, a read transaction is initiated. When the event COMPLETETRANS is set, read back this register
  [27:16] FSCOMMANDADDR — Address for the async interface. ALWAYS 0x134.
    0x134=OVR_VAL_PHASE_SEL_ADDR (ALWAYS 0x134.)
  [0] OVR_VAL_PHASE_SEL — Overridden phaseSelect value when DtcPhaseCtrl is disabled
0x400 FSCOMMAND_OVR_VAL_TDC_OFFSET0 reset 0x1B80000 (alternate view of FSCOMMAND_ANA_ISOLATION) — Send or receive command directly to/from the AdPllLte digital island. Only write to this register when FSASYNCBUSBUSY returns 0
  [31] READ — When 1, a read transaction is initiated. When the event COMPLETETRANS is set, read back this register
  [27:16] FSCOMMANDADDR — Address for the async interface. ALWAYS 0x1B8.
    0x1B8=OVR_VAL_TDC_OFFSET0_ADDR (ALWAYS 0x1B8.)
  [2:0] OVR_VAL_TDC_OFFSET0 — Override value0 for TDC offset. Also used in fast frequency jumps
0x400 FSCOMMAND_OVR_VAL_TDC_OFFSET1 reset 0x2000000 (alternate view of FSCOMMAND_ANA_ISOLATION) — Send or receive command directly to/from the AdPllLte digital island. Only write to this register when FSASYNCBUSBUSY returns 0
  [31] READ — When 1, a read transaction is initiated. When the event COMPLETETRANS is set, read back this register
  [27:16] FSCOMMANDADDR — Address for the async interface. ALWAYS 0x200.
    0x200=OVR_VAL_TDC_OFFSET1_ADDR (ALWAYS 0x200.)
  [5:3] OVR_VAL_TDC_OFFSET1 — Override value1 for TDC offset. Only used in fast frequency jumps
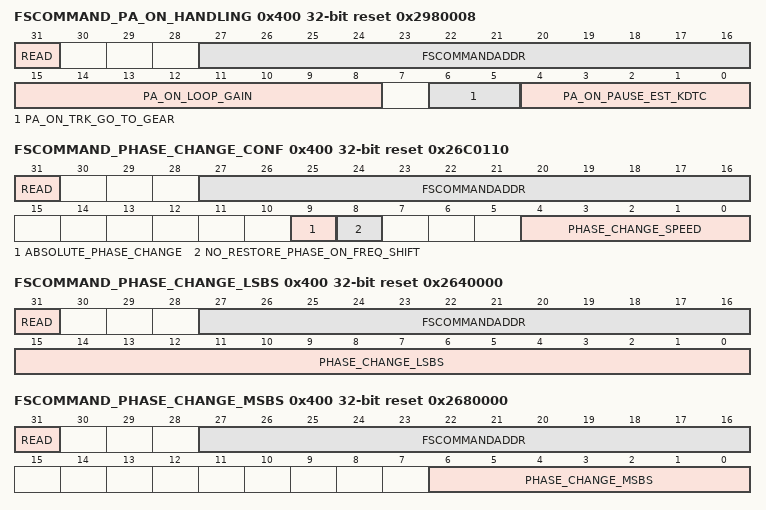
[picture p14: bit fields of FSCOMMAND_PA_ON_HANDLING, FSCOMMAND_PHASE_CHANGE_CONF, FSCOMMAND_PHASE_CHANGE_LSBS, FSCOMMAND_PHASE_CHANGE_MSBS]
0x400 FSCOMMAND_PA_ON_HANDLING reset 0x2980008 (alternate view of FSCOMMAND_ANA_ISOLATION) — Send or receive command directly to/from the AdPllLte digital island. Only write to this register when FSASYNCBUSBUSY returns 0
  [31] READ — When 1, a read transaction is initiated. When the event COMPLETETRANS is set, read back this register
  [27:16] FSCOMMANDADDR — Address for the async interface. ALWAYS 0x298.
    0x298=PA_ON_HANDLING_ADDR (ALWAYS 0x298.)
  [15:8] PA_ON_LOOP_GAIN — Other loop gain when PA is enabled. 0: Do not use. Use default
  [6:5] PA_ON_TRK_GO_TO_GEAR — Go to one of the configured gear settings when the PA gets enabled. 0: off, 1: Go to FSM_TRK_THIRD_GEAR, 2: Go to FSM_TRK_SECOND_GEAR, 3: Go to FSM_TRK_FIRST_GEAR
  [4:0] PA_ON_PAUSE_EST_KDTC — When the PA turns on we disable the input to the kDTC estimator for a while (multiplied by 8)
0x400 FSCOMMAND_PHASE_CHANGE_CONF reset 0x26C0110 (alternate view of FSCOMMAND_ANA_ISOLATION) — Send or receive command directly to/from the AdPllLte digital island. Only write to this register when FSASYNCBUSBUSY returns 0
  [31] READ — When 1, a read transaction is initiated. When the event COMPLETETRANS is set, read back this register
  [27:16] FSCOMMANDADDR — Address for the async interface. ALWAYS 0x26C.
    0x26C=PHASE_CHANGE_CONF_ADDR (ALWAYS 0x26C.)
  [9] ABSOLUTE_PHASE_CHANGE — If 1, the requested phase change is absolute, If 0, the requested phase change is relative
  [8] NO_RESTORE_PHASE_ON_FREQ_SHIFT — If 0, the phase is automatically restored when doing a frequency shift
  [4:0] PHASE_CHANGE_SPEED — How much to change the phase per clock cycle when a phase change is requested via the PHASE_CHANGE register
0x400 FSCOMMAND_PHASE_CHANGE_LSBS reset 0x2640000 (alternate view of FSCOMMAND_ANA_ISOLATION) — Send or receive command directly to/from the AdPllLte digital island. Only write to this register when FSASYNCBUSBUSY returns 0
  [31] READ — When 1, a read transaction is initiated. When the event COMPLETETRANS is set, read back this register
  [27:16] FSCOMMANDADDR — Address for the async interface. ALWAYS 0x264.
    0x264=PHASE_CHANGE_LSBS_ADDR (ALWAYS 0x264.)
  [15:0] PHASE_CHANGE_LSBS — Writing to this register will initiate a phase change. PHASE_CHANGE_CONF.ABSOLUTE_PHASE_CHANGE will decide if it is relative or absolute. Least significant bits of the value.
0x400 FSCOMMAND_PHASE_CHANGE_MSBS reset 0x2680000 (alternate view of FSCOMMAND_ANA_ISOLATION) — Send or receive command directly to/from the AdPllLte digital island. Only write to this register when FSASYNCBUSBUSY returns 0
  [31] READ — When 1, a read transaction is initiated. When the event COMPLETETRANS is set, read back this register
  [27:16] FSCOMMANDADDR — Address for the async interface. ALWAYS 0x268.
    0x268=PHASE_CHANGE_MSBS_ADDR (ALWAYS 0x268.)
  [6:0] PHASE_CHANGE_MSBS — Writing to this register will initiate a phase change. PHASE_CHANGE_CONF.ABSOLUTE_PHASE_CHANGE will decide if it is relative or absolute. Most significant bits of the value.
0x400 FSCOMMAND_PVT_TO_FIX_RATIO reset 0x1401C8 (alternate view of FSCOMMAND_ANA_ISOLATION) — Send or receive command directly to/from the AdPllLte digital island. Only write to this register when FSASYNCBUSBUSY returns 0
  [31] READ — When 1, a read transaction is initiated. When the event COMPLETETRANS is set, read back this register
  [27:16] FSCOMMANDADDR — Address for the async interface. ALWAYS 0x14.
    20=PVT_TO_FIX_RATIO_ADDR (ALWAYS 0x14.)
  [10:0] PVT_TO_FIX_RATIO — The ratio between one step in the PVT capacitor bank vs the value when all capacitors are off. Used for EstKdtc and TdcReadout
0x400 FSCOMMAND_RESET_KDTC_ACCUM_NOW reset 0x2600000 (alternate view of FSCOMMAND_ANA_ISOLATION) — Send or receive command directly to/from the AdPllLte digital island. Only write to this register when FSASYNCBUSBUSY returns 0
  [31] READ — When 1, a read transaction is initiated. When the event COMPLETETRANS is set, read back this register
  [27:16] FSCOMMANDADDR — Address for the async interface. ALWAYS 0x260.
    0x260=RESET_KDTC_ACCUM_NOW_ADDR (ALWAYS 0x260.)
  [0] RESET_KDTC_ACCUM_NOW — Manually reset the kDTC estimator accumulator now
0x400 FSCOMMAND_SAFETY_COUNTERS reset 0x23C0000 (alternate view of FSCOMMAND_ANA_ISOLATION) — Send or receive command directly to/from the AdPllLte digital island. Only write to this register when FSASYNCBUSBUSY returns 0
  [31] READ — When 1, a read transaction is initiated. When the event COMPLETETRANS is set, read back this register
  [27:16] FSCOMMANDADDR — Address for the async interface. ALWAYS 0x23C.
    0x23C=SAFETY_COUNTERS_ADDR (ALWAYS 0x23C.)
  [11:8] ACQ_BANK_OVERFLOW_CNT — Number of times there has been ACQ bank overflow since last starting the PLL. Max 15
  [7:4] TRK_BANK_OVERFLOW_CNT — Number of times there has been TRK bank overflow since last starting the PLL. Max 15
  [3:0] COLD_LOCK_RST_CNT — Number of times the cold lock reset safety mechanism has triggered since last starting the PLL. Max 15
